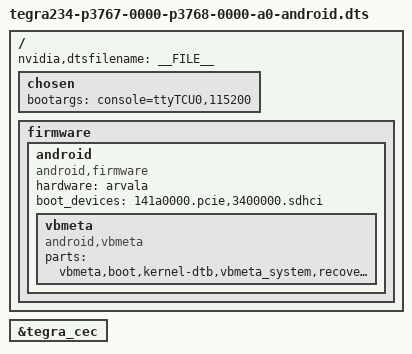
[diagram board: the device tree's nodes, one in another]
#include "tegra234-p3767-0000-p3768-0000-a0.dts"

/ {
	nvidia,dtsfilename = __FILE__;

	chosen {
		bootargs ="console=ttyTCU0,115200";
	};

	firmware {
		android {
			compatible = "android,firmware";
			hardware = "arvala";
			boot_devices = "141a0000.pcie,3400000.sdhci";
			vbmeta {
				compatible = "android,vbmeta";
				parts = "vbmeta,boot,kernel-dtb,vbmeta_system,recovery";
			};
		};
	};
};

&tegra_cec {
	status = "okay";
};
